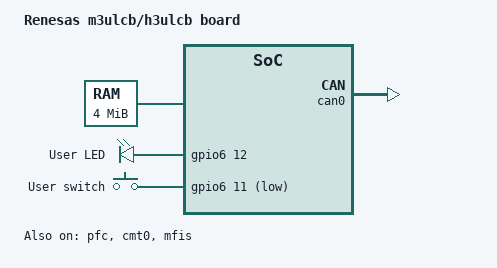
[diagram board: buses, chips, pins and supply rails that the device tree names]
/*
 * Copyright (c) 2020 IoT.bzh
 *
 * SPDX-License-Identifier: Apache-2.0
 *
 */

/dts-v1/;
#include <arm/renesas/rcar_cr7.dtsi>

/ {
	model = "Renesas m3ulcb/h3ulcb board";
	compatible = "renesas,ulcb-cr7";

	chosen {
		zephyr,sram = &sram0;
		zephyr,ipc_shm = &sram_shm;
		zephyr,ipc = &mfis;
		zephyr,can-primary = &can0;
	};

	sram_shm: memory@42000000 {
		compatible = "mmio-sram";
		reg = <0x42000000 0x400000>;
	};

	leds {
		compatible = "gpio-leds";
		user_led: led_5 {
			gpios = <&gpio6 12 GPIO_ACTIVE_HIGH>;
			label = "User LED";
		};
	};

	gpio_keys {
		compatible = "gpio-keys";
		user_button: sw3 {
			label = "User switch";
			gpios = <&gpio6 11 GPIO_ACTIVE_LOW>;
		};
	};

	display {
		compatible = "rcar_display";
		label = "DISPLAY";
	};

	vspd {
		compatible = "rcar_vspd";
		label = "rcar-vspd";
	};

	aliases {
		led0 = &user_led;
		sw0 = &user_button;
	};
};

&pfc {
	status = "okay";
};

&can0 {
	status = "okay";
};

&cmt0 {
	status = "okay";
	clock-frequency = <32000>;
};

&mfis {
	status = "okay";
};
